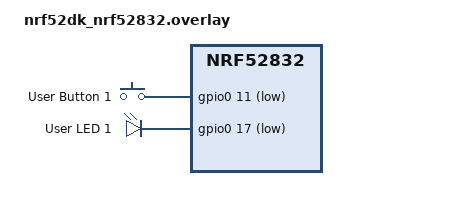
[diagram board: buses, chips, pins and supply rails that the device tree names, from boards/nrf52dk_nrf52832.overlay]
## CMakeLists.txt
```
#-------------------------------------------------------------------------------
# Zephyr Button-LED Interaction Demo Application
#
# Copyright (c) 2021 Nordic Semiconductor ASA
# SPDX-License-Identifier: Apache-2.0

cmake_minimum_required(VERSION 3.13.1)
find_package(Zephyr REQUIRED HINTS $ENV{ZEPHYR_BASE})

project(non_trivial_button_led_app)

target_sources(app PRIVATE
  src/main.cpp
  src/read.cpp
  src/react.cpp
)
```

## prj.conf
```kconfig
# Copyright (c) 2021 Nordic Semiconductor ASA
# SPDX-License-Identifier: Apache-2.0
#
# This file contains selected Kconfig options for the application.

# Enable C++ support
CONFIG_CPP=y
CONFIG_REQUIRES_FULL_LIBCPP=y

# Enable GPIO
CONFIG_GPIO=y

# Enable software debounce
#CONFIG_GPIO_DEBOUNCE=y
#CONFIG_GPIO_DEBOUNCE_TIME_MS=50

# Enable workqueue
CONFIG_SYSTEM_WORKQUEUE_STACK_SIZE=2048

# Enable zbus
CONFIG_ZBUS=y
CONFIG_ZBUS_LOG_LEVEL_INF=y
CONFIG_ZBUS_CHANNEL_NAME=y
CONFIG_ZBUS_OBSERVER_NAME=y
CONFIG_ZBUS_RUNTIME_OBSERVERS=y


# Enable logging
CONFIG_LOG=y
CONFIG_LOG_MODE_MINIMAL=y
CONFIG_MAIN_THREAD_PRIORITY=5

CONFIG_BOOT_BANNER=n
CONFIG_ASSERT=y
```

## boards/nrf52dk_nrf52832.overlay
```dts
&button1 {
    status = "okay";
    gpios = <&gpio0 11 (GPIO_PULL_UP | GPIO_ACTIVE_LOW)>;
    label = "User Button 1";
};

&led1 {
    status = "okay";
    gpios = <&gpio0 17 GPIO_ACTIVE_LOW>;
    label = "User LED 1";
};
```

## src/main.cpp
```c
/**
 * @file     main.cpp
 * @brief    Main application for button/LED interaction system
 * @author   Martin Cvitic
 * @date     2025-05-10
 * @version  1.0
 *
 * @details  Implements main application logic for:
 *           - Zbus message passing between components
 *           - LED output control
 *           - Button input with debouncing
 */

//=============================================================================
// INCLUDES
//=============================================================================
#include "read.h"
#include "react.h"
#include <zephyr/kernel.h>
#include <zephyr/logging/log.h>

//=============================================================================
// MACROS
//=============================================================================
#define LED_NODE        DT_ALIAS(led1)    ///< Device tree node for LED
#define BUTTON_NODE     DT_ALIAS(sw0)     ///< Device tree node for button

LOG_MODULE_REGISTER(main, LOG_LEVEL_INF); ///< Main application logger

#if !DT_NODE_HAS_STATUS_OKAY(BUTTON_NODE)
#error "Unsupported board: button devicetree alias is not defined"
#endif

#if !DT_NODE_HAS_STATUS_OKAY(LED_NODE)
#error "Unsupported board: LED devicetree alias is not defined"
#endif

//============================================================================= 
// STATIC VARIABLES
//=============================================================================
static const struct gpio_dt_spec button = GPIO_DT_SPEC_GET(BUTTON_NODE, gpios);
static const struct gpio_dt_spec led = GPIO_DT_SPEC_GET(LED_NODE, gpios);

//=============================================================================
// FUPUBLIC FUNCTIONS
//=============================================================================

/**
 * @brief Main application entry point
 *
 * Initializes system components and enters main processing loop.
 * 
 * @return int Application exit status (0 for success)
 */
int main(void)
{
    //---------------------------------------------------------------------
    // INITIALIZATION
    //---------------------------------------------------------------------
    ReadClass reader(button);
    ReactClass reactor(led);

    if (reader.init() != 0 || reactor.init() != 0)
    {
        LOG_ERR("Initialization failed");
        return -ENODEV;
    }

    LOG_INF("System ready. Press the button.");

    while (true)
    {
        k_sleep(K_SECONDS(1));
    }

    return 0;
}
```

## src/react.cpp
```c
/**
 * @file     react.cpp
 * @brief    LED reaction handler implementation
 * @author   Martin Cvitic
 * @date     2025-05-10
 * @version  1.0
 *
 * @details  Implements LED control logic including:
 *           - Zbus observer callback
 *           - LED blink patterns
 *           - Timed LED states
 */

//=============================================================================
// INCLUDES
//=============================================================================
#include "react.h"
#include "read.h"  // Include the header where button_msg is defined
#include <zephyr/logging/log.h>

//=============================================================================
// MACROS
//=============================================================================
LOG_MODULE_REGISTER(ReactClass, LOG_LEVEL_INF);  ///< ReactClass logger instance
ZBUS_LISTENER_DEFINE(led_observer, ReactClass::observer_cb);

//=============================================================================
// STATIC MEMBER INITIALIZATION
//=============================================================================
struct gpio_dt_spec ReactClass::led_;
struct k_work_delayable ReactClass::led_work_;
uint8_t ReactClass::blink_remaining_ = 0;
ReactClass::led_action ReactClass::current_action_ = ReactClass::NONE;


//=============================================================================
// CLASS METHOD IMPLEMENTATIONS
//=============================================================================

/**
 * @brief Construct a new ReactClass object
 * @param led_spec GPIO specification for the LED
 */
ReactClass::ReactClass(const struct gpio_dt_spec &led_spec)
{
    led_ = led_spec;
}

/**
 * @brief Initialize LED hardware and work queue
 * @return int 0 on success, negative error code on failure
 */
int ReactClass::init()
{
    k_work_init_delayable(&led_work_, led_work_handler);

    if (!gpio_is_ready_dt(&led_)) 
    {
        LOG_ERR("LED device not ready");
        return -ENODEV;
    }

    int ret = gpio_pin_configure_dt(&led_, GPIO_OUTPUT_INACTIVE);
    if (ret != 0)
    {
        LOG_ERR("Failed to configure LED: %d", ret);
        return ret;
    }

    return 0;
}

/**
 * @brief Zbus observer callback for button state changes
 * @param chan Pointer to the zbus channel that triggered the callback
 */
void ReactClass::observer_cb(const struct zbus_channel *chan)
{

    const button_msg *msg = static_cast<const button_msg *>(zbus_chan_const_msg(chan));

    k_work_cancel_delayable(&led_work_);

    if (msg->pressed) 
    {
        current_action_ = BLINK;
        blink_remaining_ = 6;  // 3 blinks (on/off pairs)
    } 
    else 
    {
        current_action_ = ON_500MS;
    }

    k_work_reschedule(&led_work_, K_NO_WAIT);
}

/**
 * @brief Work queue handler for LED state machine
 * @param work Pointer to the work structure (unused)
 */
void ReactClass::led_work_handler(struct k_work *work)
{
    (void)work;  // Explicitly unused parameter

    switch (current_action_)
    {
    case BLINK:
        if (blink_remaining_ > 0)
        {
            gpio_pin_toggle_dt(&led_);
            blink_remaining_--;
            k_work_reschedule(&led_work_, K_MSEC(100));
        } 
        else 
        {
            gpio_pin_set_dt(&led_, 0);
            current_action_ = NONE;
        }
        break;

    case ON_500MS:
        gpio_pin_set_dt(&led_, 1);
        current_action_ = OFF;
        k_work_reschedule(&led_work_, K_MSEC(500));
        break;

    case OFF:
        gpio_pin_set_dt(&led_, 0);
        current_action_ = NONE;
        break;

    case NONE:
    default:
        break;
    }
}
```

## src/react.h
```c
/**
 * @file react.h
 * @brief Header file for LED reaction class that handles GPIO and Zbus interactions
 */

 #pragma once

 #include <zephyr/kernel.h>
 #include <zephyr/zbus/zbus.h>
 #include <zephyr/drivers/gpio.h>
 #include "read.h"
 
 /**
  * @class ReactClass
  * @brief Class for managing LED reactions to button state changes via Zbus
  * 
  * This class handles LED control including blinking patterns and timed on/off states
  * in response to button state changes received through Zbus channels.
  */
 class ReactClass 
 {
 public:
     /**
      * @brief Construct a new ReactClass object
      * @param led_spec GPIO device tree specification for the LED
      */
     ReactClass(const struct gpio_dt_spec &led_spec);
 
     /**
      * @brief Initialize the LED GPIO and work queue
      * @return int 0 on success, negative error code on failure
      */
     int init();
 
     /**
      * @brief Zbus observer callback for button state changes
      * @param chan Pointer to the zbus channel that triggered the callback
      */
     static void observer_cb(const struct zbus_channel *chan);
 
     /**
      * @brief Work queue handler for LED control
      * @param work Pointer to the work structure
      */
     static void led_work_handler(struct k_work *work);
 
 private:
     static struct gpio_dt_spec led_;          ///< GPIO specification for the LED
     static struct k_work_delayable led_work_; ///< Delayed work item for LED control
     static uint8_t blink_remaining_;          ///< Counter for remaining blinks
 
     /**
      * @enum led_action
      * @brief Possible LED actions
      */
     static enum led_action
     {
         NONE,     ///< No current LED action
         BLINK,    ///< LED should blink
         ON_500MS, ///< LED should stay on for 500ms
         OFF       ///< LED should turn off
     } current_action_; ///< Current LED action state
 };
```

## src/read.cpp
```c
/**
 * @file     read.cpp
 * @brief    Button input handler implementation
 * @author   Martin Cvitic
 * @date     2025-05-10
 * @version  1.0
 *
 * @details  Implements button input handling including:
 *           - GPIO interrupt configuration
 *           - Debounce logic
 *           - Zbus message publishing
 */

//=============================================================================
// INCLUDES
//=============================================================================
#include "read.h"
#include <zephyr/logging/log.h>
#include <zephyr/zbus/zbus.h>

//=============================================================================
// MACROS
//=============================================================================
LOG_MODULE_REGISTER(ReadClass, LOG_LEVEL_INF);  ///< ReadClass logger instance

ZBUS_CHAN_DEFINE(
    button_chan,
    struct button_msg,
    NULL, NULL,
    ZBUS_OBSERVERS(led_observer),
    ZBUS_MSG_INIT(.pressed = false, .timestamp = 0)
);

//=============================================================================
// STATIC MEMBER INITIALIZATION
//=============================================================================
struct gpio_callback ReadClass::button_cb_;
struct k_work ReadClass::work_;
int64_t ReadClass::last_interrupt_time_ = 0;
ReadClass* ReadClass::instance_ = nullptr;

//=============================================================================
// CLASS METHOD IMPLEMENTATIONS
//=============================================================================

/**
 * @brief Construct a new ReadClass object
 * @param button_spec GPIO specification for the button
 */
ReadClass::ReadClass(const struct gpio_dt_spec &button_spec)
    : button_(button_spec) {}

/**
 * @brief Initialize button hardware and interrupt
 * @return int 0 on success, negative error code on failure
 */
int ReadClass::init()
{
    instance_ = this;
    k_work_init(&work_, work_handler);

    if (!gpio_is_ready_dt(&button_))
    {
        LOG_ERR("Button device not ready");
        return -ENODEV;
    }

    int ret = gpio_pin_configure_dt(&button_, GPIO_INPUT | GPIO_PULL_UP);
    if (ret != 0)
    {
        LOG_ERR("Failed to configure button: %d", ret);
        return ret;
    }

    ret = gpio_pin_interrupt_configure_dt(&button_, GPIO_INT_EDGE_BOTH);
    if (ret != 0)
    {
        LOG_ERR("Failed to configure interrupt: %d", ret);
        return ret;
    }

    gpio_init_callback(&button_cb_, isr_handler, BIT(button_.pin));
    gpio_add_callback(button_.port, &button_cb_);

    return 0;
}

/**
 * @brief Interrupt service routine for button state changes
 * @param dev Pointer to the device structure (unused)
 * @param cb Pointer to the callback structure (unused)
 * @param pins Bitmask of pins that triggered the interrupt (unused)
 */
void ReadClass::isr_handler(const struct device *dev, 
                           struct gpio_callback *cb, 
                           uint32_t pins)
{
    (void)dev;
    (void)cb;
    (void)pins;

    int64_t now = k_uptime_get();
    if ((now - last_interrupt_time_) > debounce_ms_)
    {
        k_work_submit(&instance_->work_);
        last_interrupt_time_ = now;
    }
}

/**
 * @brief Work queue handler for button state processing
 * @param work Pointer to the work structure (unused)
 */
void ReadClass::work_handler(struct k_work *work)
{
    (void)work;
    ReadClass *self = instance_;

    int val = gpio_pin_get_dt(&self->button_);
    if (val < 0)
    {
        LOG_ERR("Failed to read button");
        return;
    }

    bool pressed = (val == 0);
    button_msg msg = {
        .pressed = pressed,
        .timestamp = k_uptime_get_32()
    };

    zbus_chan_pub(&button_chan, &msg, K_NO_WAIT);
    LOG_INF("Button %s", pressed ? "PRESSED" : "RELEASED");
}
```

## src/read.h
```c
/**
 * @file read.h
 * @brief Header file for button reading class with interrupt and debounce handling
 */

 #pragma once

 #include <zephyr/device.h>
 #include <zephyr/drivers/gpio.h>
 #include <zephyr/kernel.h>
 #include <zephyr/sys/util.h>
 #include <cstdint>
 
 /**
  * @struct button_msg
  * @brief Message structure for button state changes
  */
 struct button_msg
 {
     bool pressed;        ///< Current button state (true = pressed)
     uint32_t timestamp;  ///< Timestamp when state change occurred
 };
 
 /**
  * @class ReadClass
  * @brief Class for managing button input with debouncing and interrupt handling
  *
  * This class handles GPIO button input with hardware interrupt triggering,
  * debouncing, and work queue processing for state change events.
  */
 class ReadClass
 {
 public:
     /**
      * @brief Construct a new ReadClass object
      * @param button_spec GPIO device tree specification for the button
      */
     ReadClass(const struct gpio_dt_spec &button_spec);
 
     /**
      * @brief Initialize the button GPIO and interrupt
      * @return int 0 on success, negative error code on failure
      */
     int init();
 
 #ifdef UNIT_TEST
     /**
      * @brief Interrupt service routine for button state changes
      * @param dev Pointer to the device structure
      * @param cb Pointer to the callback structure
      * @param pins Bitmask of pins that triggered the interrupt
      */
     static void isr_handler(const struct device *dev, 
                           struct gpio_callback *cb, 
                           uint32_t pins);
 
     /**
      * @brief Work queue handler for processing button state changes
      * @param work Pointer to the work structure
      */
     static void work_handler(struct k_work *work);
 #else
 private:
     static void isr_handler(const struct device *dev,
                           struct gpio_callback *cb,
                           uint32_t pins);
     static void work_handler(struct k_work *work);
 #endif
 
     struct gpio_dt_spec button_;  ///< GPIO specification for the button
 
 private:
     static struct gpio_callback button_cb_;  ///< GPIO callback structure
     static struct k_work work_;              ///< Work item for deferred processing
     static constexpr int64_t debounce_ms_ = 50;  ///< Debounce time in milliseconds
     static int64_t last_interrupt_time_;     ///< Timestamp of last interrupt
     static ReadClass* instance_;             ///< Singleton instance pointer
 };
```
